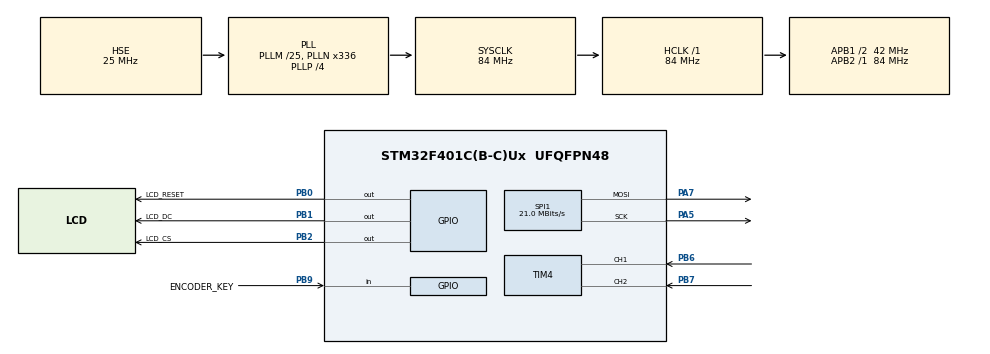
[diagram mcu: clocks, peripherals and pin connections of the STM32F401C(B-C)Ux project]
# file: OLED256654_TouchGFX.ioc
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Dma.Request0=SPI1_TX
Dma.SPI1_TX.0.Direction=DMA_MEMORY_TO_PERIPH
Dma.SPI1_TX.0.FIFOMode=DMA_FIFOMODE_DISABLE
Dma.SPI1_TX.0.Instance=DMA2_Stream3
Dma.SPI1_TX.0.MemDataAlignment=DMA_MDATAALIGN_BYTE
Dma.SPI1_TX.0.MemInc=DMA_MINC_ENABLE
Dma.SPI1_TX.0.Mode=DMA_NORMAL
Dma.SPI1_TX.0.PeriphDataAlignment=DMA_PDATAALIGN_BYTE
Dma.SPI1_TX.0.PeriphInc=DMA_PINC_DISABLE
Dma.SPI1_TX.0.Priority=DMA_PRIORITY_LOW
FREERTOS.BinarySemaphores01=EncoderSem,Dynamic,NULL
FREERTOS.Tasks01=GUI_Task,24,2048,TouchGFX_Task,As weak,NULL,Dynamic,NULL,NULL
FREERTOS.configENABLE_FPU=1
FREERTOS.configTOTAL_HEAP_SIZE=16384
FREERTOS.configUSE_NEWLIB_REENTRANT=1
Mcu.Family=STM32F4
Mcu.Name=STM32F401C(B-C)Ux
Mcu.Package=UFQFPN48
NVIC.DMA2_Stream3_IRQn=true\:5\:0\:false\:false\:true\:true\:false\:true\:true
NVIC.PriorityGroup=NVIC_PRIORITYGROUP_4
NVIC.SPI1_IRQn=true\:5\:0\:false\:false\:true\:true\:true\:true\:true
NVIC.TIM1_TRG_COM_TIM11_IRQn=true\:15\:0\:false\:false\:true\:false\:false\:true\:true
NVIC.TIM1_UP_TIM10_IRQn=true\:5\:0\:false\:false\:true\:true\:true\:true\:true
NVIC.TIM4_IRQn=true\:5\:0\:false\:false\:true\:true\:true\:true\:true
NVIC.TimeBase=TIM1_TRG_COM_TIM11_IRQn
NVIC.TimeBaseIP=TIM11
PA5.Mode=TX_Only_Simplex_Unidirect_Master
PA5.Signal=SPI1_SCK
PA7.Mode=TX_Only_Simplex_Unidirect_Master
PA7.Signal=SPI1_MOSI
PB0.GPIO_Label=LCD_RESET
PB0.GPIO_Speed=GPIO_SPEED_FREQ_HIGH
PB0.PinState=GPIO_PIN_RESET
PB0.Signal=GPIO_Output
PB1.GPIO_Label=LCD_DC
PB1.GPIO_Speed=GPIO_SPEED_FREQ_HIGH
PB1.PinState=GPIO_PIN_RESET
PB1.Signal=GPIO_Output
PB2.GPIO_Label=LCD_CS
PB2.GPIO_Speed=GPIO_SPEED_FREQ_HIGH
PB2.PinState=GPIO_PIN_RESET
PB2.Signal=GPIO_Output
PB6.GPIO_PuPd=GPIO_PULLUP
PB6.Signal=S_TIM4_CH1
PB7.GPIO_PuPd=GPIO_PULLUP
PB7.Signal=S_TIM4_CH2
PB9.GPIO_Label=ENCODER_KEY
PB9.GPIO_PuPd=GPIO_PULLUP
PB9.Signal=GPIO_Input
PH0\ -\ OSC_IN.Mode=HSE-External-Oscillator
PH0\ -\ OSC_IN.Signal=RCC_OSC_IN
PH1\ -\ OSC_OUT.Mode=HSE-External-Oscillator
PH1\ -\ OSC_OUT.Signal=RCC_OSC_OUT
ProjectManager.HeapSize=0x200
ProjectManager.StackSize=0x400
ProjectManager.TargetToolchain=STM32CubeIDE
RCC.48MHZClocksFreq_Value=48000000
RCC.AHBFreq_Value=84000000
RCC.APB1CLKDivider=RCC_HCLK_DIV2
RCC.APB1Freq_Value=42000000
RCC.APB1TimFreq_Value=84000000
RCC.APB2Freq_Value=84000000
RCC.APB2TimFreq_Value=84000000
RCC.CortexFreq_Value=84000000
RCC.HCLKFreq_Value=84000000
RCC.HSE_VALUE=25000000
RCC.HSI_VALUE=16000000
RCC.LSE_VALUE=32768
RCC.PLLM=25
RCC.PLLN=336
RCC.PLLP=RCC_PLLP_DIV4
RCC.PLLQ=7
RCC.PLLSourceVirtual=RCC_PLLSOURCE_HSE
RCC.SYSCLKFreq_VALUE=84000000
RCC.SYSCLKSource=RCC_SYSCLKSOURCE_PLLCLK
RCC.VCOOutputFreq_Value=336000000
SH.S_TIM4_CH1.0=TIM4_CH1,Encoder_Interface
SH.S_TIM4_CH2.0=TIM4_CH2,Encoder_Interface
SPI1.BaudRatePrescaler=SPI_BAUDRATEPRESCALER_4
SPI1.CalculateBaudRate=21.0 MBits/s
SPI1.Direction=SPI_DIRECTION_2LINES
SPI1.Mode=SPI_MODE_MASTER
SPI1.VirtualType=VM_MASTER
STMicroelectronics.X-CUBE-TOUCHGFX.4.21.1.ApplicationCcGraphicsJjApplication=TouchGFXOoGenerator
STMicroelectronics.X-CUBE-TOUCHGFX.4.21.1.tgfx_block_size=256
STMicroelectronics.X-CUBE-TOUCHGFX.4.21.1.tgfx_buffering_strategy=Single
STMicroelectronics.X-CUBE-TOUCHGFX.4.21.1.tgfx_custom_height=64
STMicroelectronics.X-CUBE-TOUCHGFX.4.21.1.tgfx_custom_width=256
STMicroelectronics.X-CUBE-TOUCHGFX.4.21.1.tgfx_number_of_blocks=2
STMicroelectronics.X-CUBE-TOUCHGFX.4.21.1.tgfx_oswrapper=CMSIS V2
STMicroelectronics.X-CUBE-TOUCHGFX.4.21.1.tgfx_pixel_format=Grey4\:4
STMicroelectronics.X-CUBE-TOUCHGFX.4.21.1_IsPackSelfContextualization=true
TIM10.Channel=TIM_CHANNEL_1
TIM10.OC1Preload=ENABLE
TIM10.Period=60
TIM10.Prescaler=28000-1
TIM4.ClockDivision=TIM_CLOCKDIVISION_DIV1
TIM4.EncoderMode=TIM_ENCODERMODE_TI12
TIM4.IC1Filter=1
TIM4.IC1Polarity=TIM_ICPOLARITY_RISING
TIM4.IC1Prescaler=TIM_ICPSC_DIV1
TIM4.IC2Filter=1
TIM4.IC2Polarity=TIM_ICPOLARITY_RISING
TIM4.IC2Prescaler=TIM_ICPSC_DIV1
VP_CRC_VS_CRC.Mode=CRC_Activate
VP_FREERTOS_VS_CMSIS_V2.Mode=CMSIS_V2
VP_STMicroelectronics.X-CUBE-TOUCHGFX_VS_GraphicsJjApplication_4.21.1.Mode=GraphicsJjApplication
VP_SYS_VS_tim11.Mode=TIM11
VP_TIM10_VS_ClockSourceINT.Mode=Enable_Timer
VP_TIM10_VS_no_output1.Mode=Output Compare1 No Output
board=custom

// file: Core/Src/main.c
/* USER CODE BEGIN Header */
/**
  ******************************************************************************
  * @file           : main.c
  * @brief          : Main program body
  ******************************************************************************
  * @attention
  *
  * Copyright (c) 2022 STMicroelectronics.
  * All rights reserved.
  *
  * This software is licensed under terms that can be found in the LICENSE file
  * in the root directory of this software component.
  * If no LICENSE file comes with this software, it is provided AS-IS.
  *
  ******************************************************************************
  */
/* USER CODE END Header */
#include "main.h"
#include "cmsis_os.h"
#include "app_touchgfx.h"

/* USER CODE BEGIN Includes */
#include "semphr.h"
/* USER CODE END Includes */

CRC_HandleTypeDef hcrc;

SPI_HandleTypeDef hspi1;
DMA_HandleTypeDef hdma_spi1_tx;

TIM_HandleTypeDef htim4;
TIM_HandleTypeDef htim10;

/* Definitions for GUI_Task */
osThreadId_t GUI_TaskHandle;
const osThreadAttr_t GUI_Task_attributes = {
  .name = "GUI_Task",
  .stack_size = 2048 * 4,
  .priority = (osPriority_t) osPriorityNormal,
};
/* Definitions for EncoderSem */
osSemaphoreId_t EncoderSemHandle;
const osSemaphoreAttr_t EncoderSem_attributes = {
  .name = "EncoderSem"
};
/* USER CODE BEGIN PV */

int16_t Encoder_count = 0;

/* USER CODE END PV */

void SystemClock_Config(void);
static void MX_GPIO_Init(void);
static void MX_DMA_Init(void);
static void MX_SPI1_Init(void);
static void MX_TIM10_Init(void);
static void MX_CRC_Init(void);
static void MX_TIM4_Init(void);
void TouchGFX_Task(void *argument);

int main(void)
{

  /* MCU Configuration--------------------------------------------------------*/

  /* Reset of all peripherals, Initializes the Flash interface and the Systick. */
  HAL_Init();

  /* Configure the system clock */
  SystemClock_Config();

  /* Initialize all configured peripherals */
  MX_GPIO_Init();
  MX_DMA_Init();
  MX_SPI1_Init();
  MX_TIM10_Init();
  MX_CRC_Init();
  MX_TIM4_Init();
  MX_TouchGFX_Init();
  /* Call PreOsInit function */
  MX_TouchGFX_PreOSInit();
  /* USER CODE BEGIN 2 */

  //while(1)
	//  GetData = (int16_t)__HAL_TIM_GET_COUNTER(&htim4);
  /* USER CODE END 2 */

  /* Init scheduler */
  osKernelInitialize();

  /* Create the semaphores(s) */
  /* creation of EncoderSem */
  EncoderSemHandle = osSemaphoreNew(1, 1, &EncoderSem_attributes);

  /* Create the thread(s) */
  /* creation of GUI_Task */
  GUI_TaskHandle = osThreadNew(TouchGFX_Task, NULL, &GUI_Task_attributes);

  /* Start scheduler */
  osKernelStart();

  /* We should never get here as control is now taken by the scheduler */
  /* Infinite loop */
  while (1)
  {

  }
}

void SystemClock_Config(void)
{
  RCC_OscInitTypeDef RCC_OscInitStruct = {0};
  RCC_ClkInitTypeDef RCC_ClkInitStruct = {0};

  /** Configure the main internal regulator output voltage
  */
  __HAL_RCC_PWR_CLK_ENABLE();
  __HAL_PWR_VOLTAGESCALING_CONFIG(PWR_REGULATOR_VOLTAGE_SCALE2);

  /** Initializes the RCC Oscillators according to the specified parameters
  * in the RCC_OscInitTypeDef structure.
  */
  RCC_OscInitStruct.OscillatorType = RCC_OSCILLATORTYPE_HSE;
  RCC_OscInitStruct.HSEState = RCC_HSE_ON;
  RCC_OscInitStruct.PLL.PLLState = RCC_PLL_ON;
  RCC_OscInitStruct.PLL.PLLSource = RCC_PLLSOURCE_HSE;
  RCC_OscInitStruct.PLL.PLLM = 25;
  RCC_OscInitStruct.PLL.PLLN = 336;
  RCC_OscInitStruct.PLL.PLLP = RCC_PLLP_DIV4;
  RCC_OscInitStruct.PLL.PLLQ = 7;
  if (HAL_RCC_OscConfig(&RCC_OscInitStruct) != HAL_OK)
  {
    Error_Handler();
  }

  /** Initializes the CPU, AHB and APB buses clocks
  */
  RCC_ClkInitStruct.ClockType = RCC_CLOCKTYPE_HCLK|RCC_CLOCKTYPE_SYSCLK
                              |RCC_CLOCKTYPE_PCLK1|RCC_CLOCKTYPE_PCLK2;
  RCC_ClkInitStruct.SYSCLKSource = RCC_SYSCLKSOURCE_PLLCLK;
  RCC_ClkInitStruct.AHBCLKDivider = RCC_SYSCLK_DIV1;
  RCC_ClkInitStruct.APB1CLKDivider = RCC_HCLK_DIV2;
  RCC_ClkInitStruct.APB2CLKDivider = RCC_HCLK_DIV1;

  if (HAL_RCC_ClockConfig(&RCC_ClkInitStruct, FLASH_LATENCY_2) != HAL_OK)
  {
    Error_Handler();
  }
}

static void MX_CRC_Init(void)
{

  hcrc.Instance = CRC;
  if (HAL_CRC_Init(&hcrc) != HAL_OK)
  {
    Error_Handler();
  }

}

static void MX_SPI1_Init(void)
{

  /* SPI1 parameter configuration*/
  hspi1.Instance = SPI1;
  hspi1.Init.Mode = SPI_MODE_MASTER;
  hspi1.Init.Direction = SPI_DIRECTION_2LINES;
  hspi1.Init.DataSize = SPI_DATASIZE_8BIT;
  hspi1.Init.CLKPolarity = SPI_POLARITY_LOW;
  hspi1.Init.CLKPhase = SPI_PHASE_1EDGE;
  hspi1.Init.NSS = SPI_NSS_SOFT;
  hspi1.Init.BaudRatePrescaler = SPI_BAUDRATEPRESCALER_4;
  hspi1.Init.FirstBit = SPI_FIRSTBIT_MSB;
  hspi1.Init.TIMode = SPI_TIMODE_DISABLE;
  hspi1.Init.CRCCalculation = SPI_CRCCALCULATION_DISABLE;
  hspi1.Init.CRCPolynomial = 10;
  if (HAL_SPI_Init(&hspi1) != HAL_OK)
  {
    Error_Handler();
  }

}

static void MX_TIM4_Init(void)
{

  TIM_Encoder_InitTypeDef sConfig = {0};
  TIM_MasterConfigTypeDef sMasterConfig = {0};

  htim4.Instance = TIM4;
  htim4.Init.Prescaler = 0;
  htim4.Init.CounterMode = TIM_COUNTERMODE_UP;
  htim4.Init.Period = 65535;
  htim4.Init.ClockDivision = TIM_CLOCKDIVISION_DIV1;
  htim4.Init.AutoReloadPreload = TIM_AUTORELOAD_PRELOAD_DISABLE;
  sConfig.EncoderMode = TIM_ENCODERMODE_TI12;
  sConfig.IC1Polarity = TIM_ICPOLARITY_RISING;
  sConfig.IC1Selection = TIM_ICSELECTION_DIRECTTI;
  sConfig.IC1Prescaler = TIM_ICPSC_DIV1;
  sConfig.IC1Filter = 1;
  sConfig.IC2Polarity = TIM_ICPOLARITY_RISING;
  sConfig.IC2Selection = TIM_ICSELECTION_DIRECTTI;
  sConfig.IC2Prescaler = TIM_ICPSC_DIV1;
  sConfig.IC2Filter = 1;
  if (HAL_TIM_Encoder_Init(&htim4, &sConfig) != HAL_OK)
  {
    Error_Handler();
  }
  sMasterConfig.MasterOutputTrigger = TIM_TRGO_RESET;
  sMasterConfig.MasterSlaveMode = TIM_MASTERSLAVEMODE_DISABLE;
  if (HAL_TIMEx_MasterConfigSynchronization(&htim4, &sMasterConfig) != HAL_OK)
  {
    Error_Handler();
  }
  /* USER CODE BEGIN TIM4_Init 2 */
  HAL_TIM_Encoder_Start_IT(&htim4, TIM_CHANNEL_ALL);
  //__HAL_TIM_ENABLE_IT(&htim4, TIM_IT_UPDATE);
  /* USER CODE END TIM4_Init 2 */

}

static void MX_TIM10_Init(void)
{

  TIM_OC_InitTypeDef sConfigOC = {0};

  htim10.Instance = TIM10;
  htim10.Init.Prescaler = 28000-1;
  htim10.Init.CounterMode = TIM_COUNTERMODE_UP;
  htim10.Init.Period = 60;
  htim10.Init.ClockDivision = TIM_CLOCKDIVISION_DIV1;
  htim10.Init.AutoReloadPreload = TIM_AUTORELOAD_PRELOAD_DISABLE;
  if (HAL_TIM_Base_Init(&htim10) != HAL_OK)
  {
    Error_Handler();
  }
  if (HAL_TIM_OC_Init(&htim10) != HAL_OK)
  {
    Error_Handler();
  }
  sConfigOC.OCMode = TIM_OCMODE_TIMING;
  sConfigOC.Pulse = 0;
  sConfigOC.OCPolarity = TIM_OCPOLARITY_HIGH;
  sConfigOC.OCFastMode = TIM_OCFAST_DISABLE;
  if (HAL_TIM_OC_ConfigChannel(&htim10, &sConfigOC, TIM_CHANNEL_1) != HAL_OK)
  {
    Error_Handler();
  }
  __HAL_TIM_ENABLE_OCxPRELOAD(&htim10, TIM_CHANNEL_1);
  /* USER CODE BEGIN TIM10_Init 2 */
  HAL_TIM_IC_Start_IT(&htim10, TIM_CHANNEL_1);
  /* USER CODE END TIM10_Init 2 */

}

static void MX_DMA_Init(void)
{

  /* DMA controller clock enable */
  __HAL_RCC_DMA2_CLK_ENABLE();

  /* DMA interrupt init */
  /* DMA2_Stream3_IRQn interrupt configuration */
  HAL_NVIC_SetPriority(DMA2_Stream3_IRQn, 5, 0);
  HAL_NVIC_EnableIRQ(DMA2_Stream3_IRQn);

}

static void MX_GPIO_Init(void)
{
  GPIO_InitTypeDef GPIO_InitStruct = {0};

  /* GPIO Ports Clock Enable */
  __HAL_RCC_GPIOH_CLK_ENABLE();
  __HAL_RCC_GPIOA_CLK_ENABLE();
  __HAL_RCC_GPIOB_CLK_ENABLE();

  /*Configure GPIO pin Output Level */
  HAL_GPIO_WritePin(GPIOB, LCD_RESET_Pin|LCD_DC_Pin|LCD_CS_Pin, GPIO_PIN_RESET);

  /*Configure GPIO pins : LCD_RESET_Pin LCD_DC_Pin LCD_CS_Pin */
  GPIO_InitStruct.Pin = LCD_RESET_Pin|LCD_DC_Pin|LCD_CS_Pin;
  GPIO_InitStruct.Mode = GPIO_MODE_OUTPUT_PP;
  GPIO_InitStruct.Pull = GPIO_NOPULL;
  GPIO_InitStruct.Speed = GPIO_SPEED_FREQ_HIGH;
  HAL_GPIO_Init(GPIOB, &GPIO_InitStruct);

  /*Configure GPIO pin : ENCODER_KEY_Pin */
  GPIO_InitStruct.Pin = ENCODER_KEY_Pin;
  GPIO_InitStruct.Mode = GPIO_MODE_INPUT;
  GPIO_InitStruct.Pull = GPIO_PULLUP;
  HAL_GPIO_Init(ENCODER_KEY_GPIO_Port, &GPIO_InitStruct);

}

/* USER CODE BEGIN 4 */
void HAL_TIM_OC_DelayElapsedCallback(TIM_HandleTypeDef *htim)
{
	if(htim->Instance == TIM10)
		touchgfxSignalVSync();
}

//void HAL_TIM_IC_CaptureCallback(TIM_HandleTypeDef *htim) // Can add your own flags you need in the capture interrupt
//{
//	static int16_t prev_data = 0;
//	static BaseType_t xHigherPriorityTaskWoken;
//
//	if(htim->Instance == TIM4)
//	{
//		Encoder_count = ((int16_t)__HAL_TIM_GET_COUNTER(&htim4)) / 4;
//
//
//		xSemaphoreGiveFromISR(EncoderSemHandle, xHigherPriorityTaskWoken);
//		if( xHigherPriorityTaskWoken == pdTRUE )
//		{
//	     /* Выдача семафора разблокирует задачу, и приоритет разблокированной
//	        задачи выше, чем у текущей выполняющейся задачи - поэтому контекст
//	        выполнения переключается принудительно в разблокированную (с более
//	        высоким приоритетом) задачу.*/
//			portYIELD();
//		}
//	}
//}

/* USER CODE END 4 */

__weak void TouchGFX_Task(void *argument)
{
  for(;;)
  {
    osDelay(1);
  }
}

void HAL_TIM_PeriodElapsedCallback(TIM_HandleTypeDef *htim)
{
  if (htim->Instance == TIM11) {
    HAL_IncTick();
  }
}

void Error_Handler(void)
{
  __disable_irq();
  while (1)
  {
  }
}
